# STM32C593xx register map
File version: 1.0
Registers are 32-bit, read-write, reset 0x0 unless marked. A register's access mark holds for its fields unless they carry their own. Offsets are from the block's base; [hi:lo] are bit positions; {n}, {i} and the like mark numbered series; 'fields as' and 'values as' point back to an identical list.

## CRC — CRC calculation unit
Base 0x40023000
0x00 DR — CRC Data register
  [31:0] DR — Data register bits
0x04 IDR — CRC Independent data register
  [31:0] IDR — General-purpose 32-bits data register bits
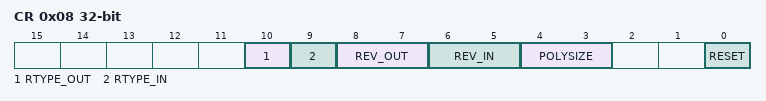
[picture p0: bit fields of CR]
0x08 CR — CRC Control register
  [10] RTYPE_OUT — Reverse type output
  [9] RTYPE_IN — Reverse type input
  [8:7] REV_OUT — REV_OUT Reverse Output Data bits
  [6:5] REV_IN — REV_IN Reverse Input Data bits
  [4:3] POLYSIZE — Polynomial size bits
  [0] RESET — RESET the CRC computation unit bit
0x10 INIT — Initial CRC value register
  [31:0] INIT — Initial CRC value bits
0x14 POL — CRC polynomial register
  [31:0] POL — Coefficients of the polynomial

## CORDIC
Base 0x40023800
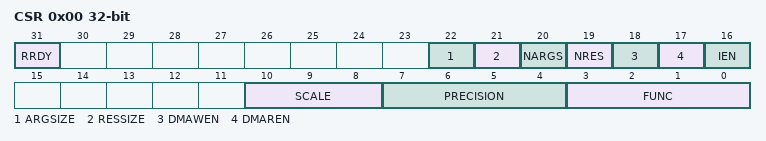
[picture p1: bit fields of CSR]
0x00 CSR — CORDIC control and status register
  [31] RRDY — Result Ready Flag
  [22] ARGSIZE — Width of input data
  [21] RESSIZE — Width of output data
  [20] NARGS — Number of arguments in RDATA register
  [19] NRES — Number of results in WDATA register
  [18] DMAWEN — DMA Write channel Enable
  [17] DMAREN — DMA Read channel Enable
  [16] IEN — Interrupt Enable
  [10:8] SCALE — Scaling factor
  [7:4] PRECISION
  [3:0] FUNC — Function
0x04 WDATA — CORDIC argument register
  [31:0] ARG — Input Argument
0x08 RDATA ro — CORDIC result register
  [31:0] RES — Output Result

## RAMCFG
Base 0x40026000
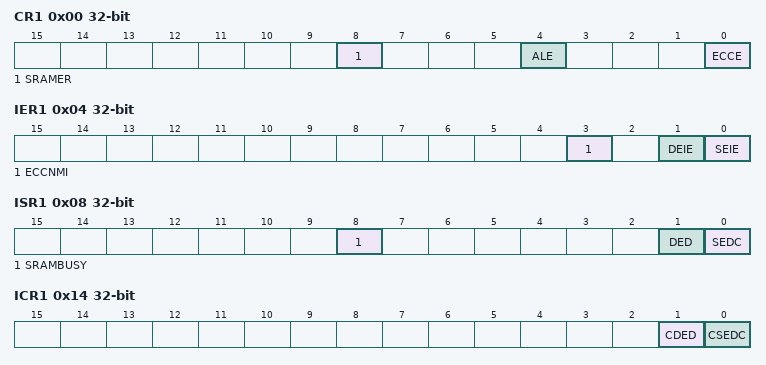
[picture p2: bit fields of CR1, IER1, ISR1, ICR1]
0x00 CR1 — RAMCFG control register
  [8] SRAMER — SRAM erase
  [4] ALE — Address latch enable
  [0] ECCE — ECC enable
0x04 IER1 — RAMCFG interrupt enable register
  [3] ECCNMI — Double error NMI
  [1] DEIE — ECC double error interrupt enable
  [0] SEIE — ECC single error interrupt enable
0x08 ISR1 ro — RAMCFG interrupt status register
  [8] SRAMBUSY — SRAM busy with erase operation
  [1] DED — ECC double error detected
  [0] SEDC
0x0C SEAR1 ro — RAMCFG ECC single error address register
  [31:0] ESEA — ECC single error address
0x10 DEAR1 ro — RAMCFG ECC double error address register
  [31:0] EDEA — ECC double error address
0x14 ICR1 — RAMCFG interrupt clear register
  [1] CDED — Clear ECC double error detected
  [0] CSEDC
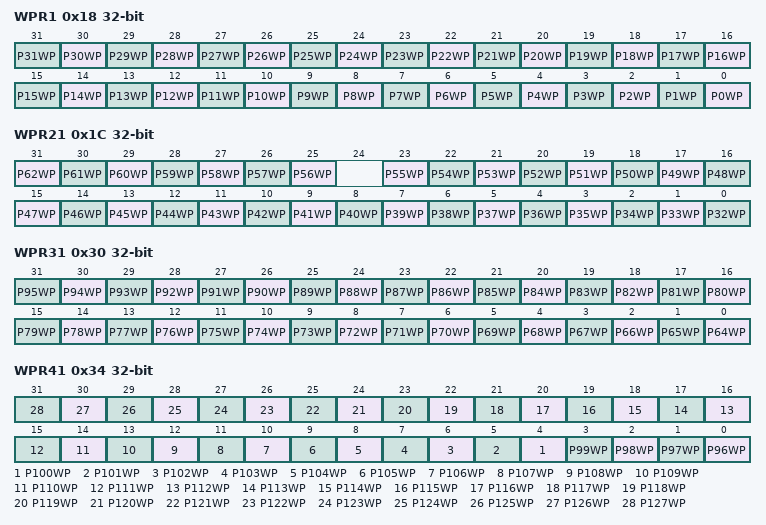
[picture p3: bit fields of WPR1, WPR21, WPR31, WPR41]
0x18 WPR1 — RAMCFG write protection register 1
  [n] P{n}WP (n=0..31) — Write Protection Page {n:02}
0x1C WPR21 — RAMCFG write protection register 2
  [n-31] P{n}WP (n=56..62) — Write Protection Page {n}
  [n-32] P{n}WP (n=32..55) — Write Protection Page {n}
0x24 ECCKEYR1 — RAMCFG ECC key register
  [7:0] ECCKEY — ECC write protection key
0x28 ERKEYR1 — RAMCFG erase key register
  [7:0] ERASEKEY — Erase write protection key
0x30 WPR31 — RAMCFG memory 2 write protection register 3
  [n-64] P{n}WP (n=64..95) — Write Protection Page {n}
0x34 WPR41 — RAMCFG memory 2 write protection register 4
  [n-96] P{n}WP (n=96..127) — Write Protection Page {n}
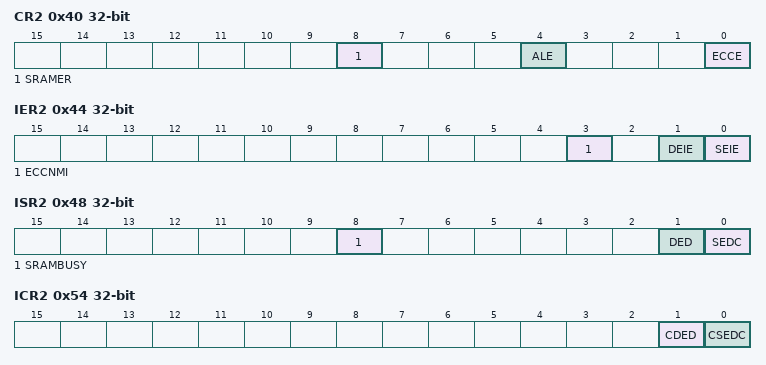
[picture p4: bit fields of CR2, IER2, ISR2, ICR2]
0x40 CR2 — RAMCFG control register
  fields as CR1
0x44 IER2 — RAMCFG interrupt enable register
  fields as IER1
0x48 ISR2 ro — RAMCFG interrupt status register
  fields as ISR1
0x4C SEAR2 ro — RAMCFG ECC single error address register
  [31:0] ESEA — ECC single error address
0x50 DEAR2 ro — RAMCFG ECC double error address register
  [31:0] EDEA — ECC double error address
0x54 ICR2 — RAMCFG interrupt clear register
  [1] CDED — Clear ECC double error detected
  [0] CSEDC
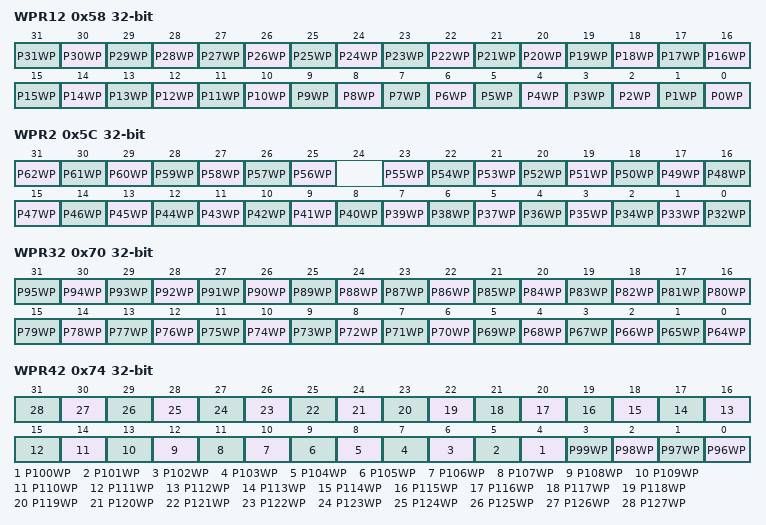
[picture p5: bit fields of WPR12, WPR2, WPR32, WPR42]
0x58 WPR12 — RAMCFG write protection register 1
  [n] P{n}WP (n=0..31) — Write Protection Page {n:02}
0x5C WPR2 — RAMCFG write protection register 2
  fields as WPR21
0x64 ECCKEYR2 — RAMCFG ECC key register
  [7:0] ECCKEY — ECC write protection key
0x68 ERKEYR2 — RAMCFG erase key register
  [7:0] ERASEKEY — Erase write protection key
0x70 WPR32 — RAMCFG memory 2 write protection register 3
  [n-64] P{n}WP (n=64..95) — Write Protection Page {n}
0x74 WPR42 — RAMCFG memory 2 write protection register 4
  [n-96] P{n}WP (n=96..127) — Write Protection Page {n}
